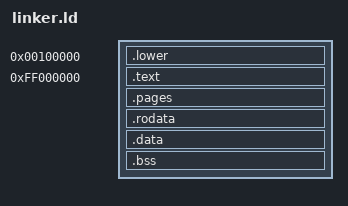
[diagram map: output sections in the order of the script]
ENTRY(lower_start)

LOADER_SIZE           = 0x00100000;
LOADER_PAGE_NUMBER    = ((LOADER_SIZE  - 1) >> 12) + 1;
LOADER_DIR_NUMBER     = ((LOADER_PAGE_NUMBER - 1) >> 10) + 1;

LOWER_PHYSICAL_BASE   = 0x00100000;
LOWER_PHYSICAL_PAGE   = LOWER_PHYSICAL_BASE >> 12;
LOWER_PHYSICAL_DIR    = LOWER_PHYSICAL_PAGE >> 10;

UPPER_VIRTUAL_BASE    = 0xFF000000;
UPPER_VIRTUAL_PAGE    = UPPER_VIRTUAL_BASE >> 12;
UPPER_VIRTUAL_DIR     = UPPER_VIRTUAL_PAGE >> 10;
KERNEL_STACK_TOP      = UPPER_VIRTUAL_BASE;

UPPER_SIZE            = 0x01000000;
UPPER_PAGE_NUMBER     = ((UPPER_SIZE - 1) >> 12) + 1;
UPPER_DIR_NUMBER      = ((UPPER_PAGE_NUMBER - 1) >> 10) + 1;

TOTAL_PAGE_NUMBER     = 0x00100000;
TOTAL_DIR_NUMBER      = ((TOTAL_PAGE_NUMBER - 1) >> 10) + 1;

SECTIONS
{
	. = LOADER_SIZE;

  .lower BLOCK(4K) : ALIGN(4K)
  {
		*(.multiboot)
    *(.lower)
  }

  UPPER_PHYSICAL_BASE = ALIGN(4K);
  UPPER_PHYSICAL_PAGE = UPPER_PHYSICAL_BASE >> 12;
  UPPER_PHYSICAL_DIR  = UPPER_PHYSICAL_PAGE >> 10;

  LOWER_SIZE        = UPPER_PHYSICAL_BASE - LOADER_SIZE;
  LOWER_PAGE_NUMBER = ((LOWER_SIZE - 1) >> 12) + 1;
  LOWER_DIR_NUMBER  = ((LOWER_PAGE_NUMBER - 1) >> 10) + 1;

  UPPER_OFFSET        = UPPER_VIRTUAL_BASE - UPPER_PHYSICAL_BASE;
  UPPER_PAGE_OFFSET   = UPPER_VIRTUAL_PAGE - UPPER_PHYSICAL_PAGE;
  UPPER_DIR_OFFSET    = UPPER_VIRTUAL_DIR  - UPPER_PHYSICAL_DIR;

  . = UPPER_VIRTUAL_BASE;

	.text ALIGN(4K) : AT(ADDR(.text) - UPPER_OFFSET)
	{
		*(.text)
	}

  DIRECTORY_TABLE = ALIGN(4K);
  PAGE_TABLE = DIRECTORY_TABLE + 4K;
  PHYSICAL_DIRECTORY_TABLE = DIRECTORY_TABLE - UPPER_OFFSET;
  PHYSICAL_PAGE_TABLE = PAGE_TABLE - UPPER_OFFSET;

  .pages ALIGN(4K) : AT(ADDR(.pages) - UPPER_OFFSET)
  {
    *(.pages)
  }

	.rodata ALIGN(4K) : AT(ADDR(.rodata) - UPPER_OFFSET)
	{
		*(.rodata)
	}

	.data ALIGN(4K) : AT(ADDR(.data) - UPPER_OFFSET)
	{
		*(.data)
	}

  .bss ALIGN(4K) : AT(ADDR(.data) - UPPER_OFFSET)
  {
    *(.bss)
  }

}
